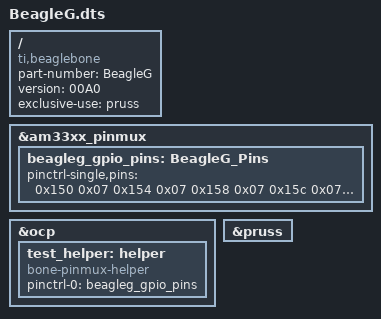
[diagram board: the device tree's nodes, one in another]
/*
 * Based on github.com/jadonk/validation-scripts/tree/master/test-capemgr
 * Copyright (C) 2012 Texas Instruments Incorporated - http://www.ti.com/
 *
 * This program is free software; you can redistribute it and/or modify
 * it under the terms of the GNU General Purpose License Version 2 as
 * published by the Free Software Foundation
 *
 * To create the binary representation that the device manager can handle, run
 *   make BeagleG-00A0.dtbo
 * (The binary fill is checked into github, so this is only needed if you are
 *  modifying this file)
 * See beagleg-cape-pinmux.sh how to enable.
 */

/dts-v1/;
/plugin/;

/{
    compatible = "ti,beaglebone", "ti,beaglebone-black";
    part-number = "BeagleG";  /* BeagleG/Bumps 'cape' */
    version = "00A0";

    exclusive-use = "pruss";   /* TODO: mention all the GPIO pins */

    fragment@0 {
        target = <&am33xx_pinmux>;
        __overlay__ {
            beagleg_gpio_pins: BeagleG_Pins {
                pinctrl-single,pins = <
		    /* Offset Mode Description */
		    /* Motor step pins GPIO-0 */
		    0x150 0x07 /* GPIO0[2] ; step axis 0 */
		    0x154 0x07 /* GPIO0[3] ; step axis 1 */
		    0x158 0x07 /* GPIO0[4] ; step axis 2 */
		    0x15c 0x07 /* GPIO0[5] ; step axis 3 */
		    0x164 0x07 /* GPIO0[7] ; step axis 4 */
		    0x180 0x07 /* GPIO0[14]; step axis 5 */
		    0x184 0x07 /* GPIO0[15]; step axis 5 */
		    0x1b4 0x07 /* GPIO0[20]; step axis 7 */

		    /* Motor direction pins; GPIO-1 */
		    0x030 0x07 /* GPIO1[12]; dir axis 0 */
		    0x034 0x07 /* GPIO1[13]; dir axis 1 */
		    0x038 0x07 /* GPIO1[14]; dir axis 2 */
		    0x03c 0x07 /* GPIO1[15]; dir axis 3 */
		    0x040 0x07 /* GPIO1[16]; dir axis 4 */
		    0x044 0x07 /* GPIO1[17]; dir axis 5 */
		    0x048 0x07 /* GPIO1[18]; dir axis 6 */
		    0x04c 0x07 /* GPIO1[19]; dir axis 7 */

		    /* Motor enable */
		    0x078 0x17 /* GPIO1[28] Motor Enable, pull up */
		    
		    /* Aux */
		    0x070 0x07 /* GPIO0[30], pull-down; AUX 1 */
		    0x074 0x07 /* GPIO0[31], pull-down; AUX 2 */

		    /* end-switches: GPIO-0 23, 26, 27 */
		    0x024 0x37  /* GPIO0[23], pull-up; end-x */
		    0x028 0x37  /* GPIO0[26], pull-up; end-y */
		    0x02c 0x37  /* GPIO0[27], pull-up; end-z */

		    /* PWM outputs */
		    0x090 0x02 /* Timer 4, pull-down; PWM_3 */
		    0x09c 0x02 /* Timer 5, pull-down; PWM_1 */
		    0x098 0x02 /* Timer 6, pull-down; PWM_2 */
		    0x094 0x02 /* Timer 7, pull-down; PWM_4 */
                >;
            };
        };
    };

    fragment@1 {
        target = <&ocp>;
        __overlay__ {
            test_helper: helper {
                compatible = "bone-pinmux-helper";
                pinctrl-names = "default";
                pinctrl-0 = <&beagleg_gpio_pins>;
                status = "okay";
            };
        };
    };

   fragment@2{
        target = <&pruss>;
        __overlay__ {
            status = "okay";
        };
   };
};
